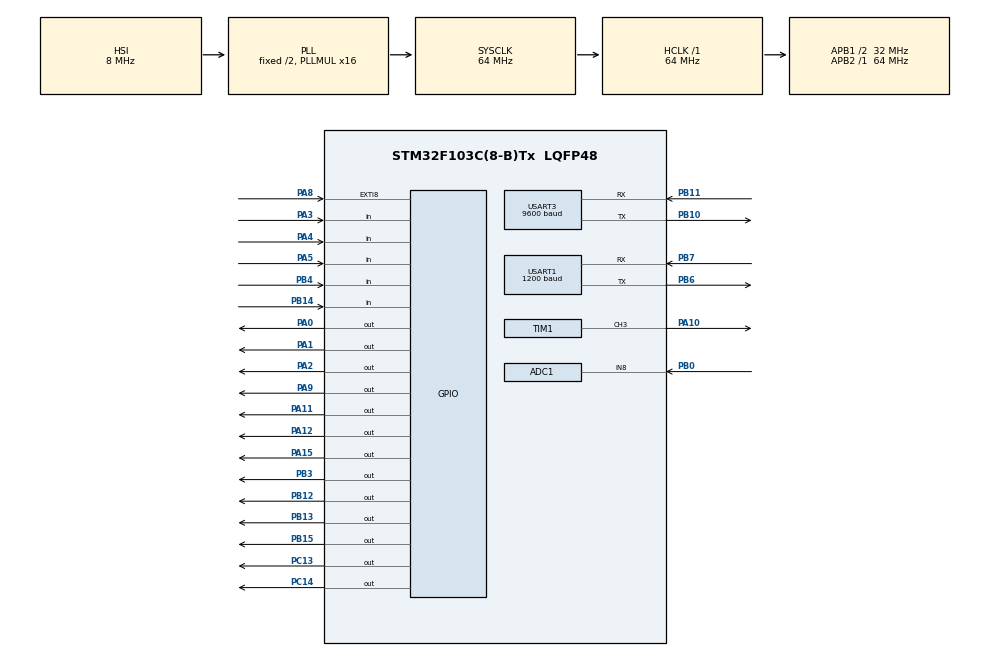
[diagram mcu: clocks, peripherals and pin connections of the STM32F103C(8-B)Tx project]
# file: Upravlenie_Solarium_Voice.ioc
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ADC1.Channel-0\#ChannelRegularConversion=ADC_CHANNEL_8
ADC1.ContinuousConvMode=DISABLE
ADC1.DataAlign=ADC_DATAALIGN_RIGHT
ADC1.DiscontinuousConvMode=DISABLE
ADC1.EnableAnalogWatchDog=false
ADC1.EnableRegularConversion=ENABLE
ADC1.ExternalTrigConv=ADC_SOFTWARE_START
ADC1.InjNumberOfConversion=0
ADC1.NbrOfConversion=1
ADC1.NbrOfConversionFlag=1
ADC1.Rank-0\#ChannelRegularConversion=1
ADC1.SamplingTime-0\#ChannelRegularConversion=ADC_SAMPLETIME_1CYCLE_5
ADC1.ScanConvMode=ADC_SCAN_DISABLE
ADC1.master=1
IWDG.Prescaler=IWDG_PRESCALER_256
Mcu.Family=STM32F1
Mcu.Name=STM32F103C(8-B)Tx
Mcu.Package=LQFP48
NVIC.ADC1_2_IRQn=true\:0\:0\:false\:true\:true\:1\:true\:true\:true
NVIC.EXTI9_5_IRQn=true\:0\:0\:false\:false\:true\:true\:true\:true
NVIC.PriorityGroup=NVIC_PRIORITYGROUP_4
NVIC.USART1_IRQn=true\:0\:0\:false\:false\:true\:true\:true\:true
NVIC.USART3_IRQn=true\:0\:0\:false\:false\:true\:true\:true\:true
PA0-WKUP.Signal=GPIO_Output
PA1.Signal=GPIO_Output
PA10.Signal=S_TIM1_CH3
PA11.Signal=GPIO_Output
PA12.Signal=GPIO_Output
PA13.Mode=Serial_Wire
PA13.Signal=SYS_JTMS-SWDIO
PA14.Mode=Serial_Wire
PA14.Signal=SYS_JTCK-SWCLK
PA15.Signal=GPIO_Output
PA2.Signal=GPIO_Output
PA3.GPIO_PuPd=GPIO_PULLUP
PA3.Signal=GPIO_Input
PA4.GPIO_PuPd=GPIO_PULLUP
PA4.Signal=GPIO_Input
PA5.GPIO_PuPd=GPIO_PULLUP
PA5.Signal=GPIO_Input
PA8.GPIO_PuPd=GPIO_PULLUP
PA8.Signal=GPXTI8
PA9.Signal=GPIO_Output
PB0.Signal=ADCx_IN8
PB10.Mode=Asynchronous
PB10.Signal=USART3_TX
PB11.GPIO_PuPd=GPIO_PULLUP
PB11.Mode=Asynchronous
PB11.Signal=USART3_RX
PB12.Signal=GPIO_Output
PB13.Signal=GPIO_Output
PB14.Signal=GPIO_Input
PB15.Signal=GPIO_Output
PB3.Signal=GPIO_Output
PB4.Signal=GPIO_Input
PB6.Mode=Asynchronous
PB6.Signal=USART1_TX
PB7.GPIO_PuPd=GPIO_PULLUP
PB7.Mode=Asynchronous
PB7.Signal=USART1_RX
PC13-TAMPER-RTC.Signal=GPIO_Output
PC14-OSC32_IN.Signal=GPIO_Output
PD0-OSC_IN.Mode=HSE-External-Oscillator
PD0-OSC_IN.Signal=RCC_OSC_IN
PD1-OSC_OUT.Mode=HSE-External-Oscillator
PD1-OSC_OUT.Signal=RCC_OSC_OUT
ProjectManager.HeapSize=0x200
ProjectManager.StackSize=0x400
ProjectManager.TargetToolchain=STM32CubeIDE
RCC.ADCPresc=RCC_ADCPCLK2_DIV6
RCC.AHBFreq_Value=64000000
RCC.APB1CLKDivider=RCC_HCLK_DIV2
RCC.APB1Freq_Value=32000000
RCC.APB1TimFreq_Value=64000000
RCC.APB2Freq_Value=64000000
RCC.APB2TimFreq_Value=64000000
RCC.HCLKFreq_Value=64000000
RCC.PLLMUL=RCC_PLL_MUL16
RCC.SYSCLKFreq_VALUE=64000000
RCC.SYSCLKSource=RCC_SYSCLKSOURCE_PLLCLK
RCC.USBFreq_Value=64000000
SH.ADCx_IN8.0=ADC1_IN8,IN8
SH.S_TIM1_CH3.0=TIM1_CH3,PWM Generation3 CH3
TIM1.AutoReloadPreload=TIM_AUTORELOAD_PRELOAD_ENABLE
TIM1.Channel-PWM\ Generation3\ CH3=TIM_CHANNEL_3
TIM1.ClockDivision=TIM_CLOCKDIVISION_DIV1
TIM1.CounterMode=TIM_COUNTERMODE_DOWN
TIM1.OCMode_PWM-PWM\ Generation3\ CH3=TIM_OCMODE_PWM2
TIM1.OCPolarity_3=TIM_OCPOLARITY_LOW
TIM1.Period=31000
TIM1.Prescaler=19
TIM1.Pulse-PWM\ Generation3\ CH3=8000
TIM2.AutoReloadPreload=TIM_AUTORELOAD_PRELOAD_ENABLE
TIM2.Period=5000
TIM2.Prescaler=16
USART1.BaudRate=1200
USART1.VirtualMode=VM_ASYNC
USART3.BaudRate=9600
USART3.VirtualMode=VM_ASYNC
VP_IWDG_VS_IWDG.Mode=IWDG_Activate
VP_TIM1_VS_ClockSourceINT.Mode=Internal
VP_TIM2_VS_ClockSourceINT.Mode=Internal
board=Upravlenie_Solarium_Voice

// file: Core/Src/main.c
/* USER CODE BEGIN Header */
/**
  ******************************************************************************
  * @file           : main.c
  * @brief          : Main program body
  ******************************************************************************
  * @attention
  *
  * Copyright (c) 2024 STMicroelectronics.
  * All rights reserved.
  *
  * This software is licensed under terms that can be found in the LICENSE file
  * in the root directory of this software component.
  * If no LICENSE file comes with this software, it is provided AS-IS.
  *
  ******************************************************************************
  */
/* USER CODE END Header */
#include "main.h"

/* USER CODE BEGIN Includes */
#include "string.h"
#include "max7219.h"
#include "LedControl.h"
#include "math.h"
#include "DFPlayer.h"
#include "eeprom.h"
#include "stdlib.h"

#define INPUT_INTERNAL 	(0)
#define INPUT_EXTERNAL 	(1)
#define STATUS_FREE    (0L)
#define STATUS_WAITING (3L)
#define STATUS_WORKING (1L)
#define STATUS_COOLING (2L)
#define MULTIPLIER     (1)
#define START_COUNTER_TIME  (1000L*MULTIPLIER)
#define ENTER_SERVICE_DELAY (2000L*MULTIPLIER)
#define SERVICE_NEXT_DELAY  (400*MULTIPLIER)
#define EXIT_SERVICE_TIME   (1200L*MULTIPLIER)
#define START_DELAY         (200L*MULTIPLIER)

// Virtual addreses
#define ADDRESS_HOURS_H		1
#define ADDRESS_HOURS_L		2
#define ADDRESS_MINUTES		3
#define ADDRESS_ADDRESSE	4
#define ADDRESS_PRE_TIME	5
#define ADDRESS_COOL_TIME	6
#define ADDRESS_EXT_MODE	7
#define ADDRESS_TEMP_MIN	8
#define ADDRESS_TEMP_MAX	9

// Buttons
#define BUTTON_PLUS      (1<<0x02)
#define BUTTON_MINUS     (1<<0x03)
#define BUTTON_START     (1<<0x00)
#define BUTTON_STOP      (1<<0x01)

#define BUTTON_AQUA      (1<<0x08)
#define BUTTON_FAN_PLUS  (1<<0x06)
#define BUTTON_FAN_MINUS (1<<0x07)
#define BUTTON_VOL_PLUS  (1<<0x04)
#define BUTTON_VOL_MINUS (1<<0x05)

#define ON 100
#define OFF 0
/* USER CODE END Includes */

ADC_HandleTypeDef hadc1;

IWDG_HandleTypeDef hiwdg;

TIM_HandleTypeDef htim1;
TIM_HandleTypeDef htim2;

UART_HandleTypeDef huart1;
UART_HandleTypeDef huart3;

/* USER CODE BEGIN PV */
/* Private variables ---------------------------------------------------------*/
int key_states;
LedControl led_control;
__IO uint32_t TimingDelay;
int tim_reload_value = 31000;
int Gv_SystickCounter;
volatile uint32_t g_ADCValue;
volatile uint32_t raw_temp;
volatile uint32_t g_ADCMeanValue;
uint32_t g_MeasurementNumber;
uint32_t g_Temperature;
unsigned char selected_unput;

unsigned char controller_address = 0x0e;
int curr_status;
int prev_status;
int curr_time;
int flash_mode = 0;
int dac_out_counter;
int dac_ping_pong_state;
int dac_prev_ping_pong_state;
int dac_current_block;
int dac_current_message;
int fade_out_counter;
int fade_in_counter;
int silence_counter;
int colaruim_lamps_state;
int lamps_state;

uint16_t data = 0;
unsigned char  time_to_set = 0;
unsigned int   work_hours[3] = {0,0,0}; //HH HL MM - Hours[2], Minutes[1]
unsigned char  preset_pre_time = 7;
unsigned char  preset_cool_time = 3;
unsigned char  temp_min_threshold;
unsigned char  temp_max_threshold;
unsigned char  ext_mode = 0;
unsigned char  lamps_mode = 0;
unsigned char  temperature_current;
unsigned char  last_rx_address;
unsigned int   error_code;
int start_counter = 0;
int last_button = 0;
int prev_button = 0;
int display_data;
int pre_time, main_time, cool_time;
unsigned int Gv_miliseconds = 0;
int Gv_UART_Timeout = 1000; // Timeout in mSec
int pre_time_sent = 0, main_time_sent = 0, cool_time_sent = 0;
int rx_state= 0;
int percent_aquafresh = 0, percent_licevi = 0, percent_fan1 = 0, percent_fan2 = 0;
int minute_counter =0;
int zero_crossed = 0;
int aqua_fresh_level = 0;
volatile int volume_level = 5;
volatile int fan_level = 7;
uint32_t tim_base=7; // Timer 2 time delay
unsigned int external_read = 0;
static int startup_delay = 0;
static int stop_delay = 0;
int current_folder_index, current_file_index;

char digits[3];
// for Display:
int refresh_counter = 0;
int flash_counter = 0;
// for Display:
int led_counter = 0;
int digit_num = 0;
__IO uint32_t LsiFreq = 40000;

/* Application general parameters */
#define VDD_APPLI                      ((uint32_t) 3300)    /* Value of analog voltage supply Vdda (unit: mV) */
#define RANGE_8BITS                    ((uint32_t)  255)    /* Max digital value for a full range of 8 bits */
#define RANGE_12BITS                   ((uint32_t) 4095)    /* Max digital value for a full range of 12 bits */

/* ADC parameters */
#define ADCCONVERTEDVALUES_BUFFER_SIZE ((uint32_t)  256)    /* Size of array containing ADC converted values */
#define ADC_36_6_DEGREE_VALUE (1024 - 0x617)
#define ADC_0_DEGREE_VALUE (1024 - 0xB70)

/* USER CODE END PV */

void SystemClock_Config(void);
static void MX_GPIO_Init(void);
static void MX_ADC1_Init(void);
static void MX_IWDG_Init(void);
static void MX_TIM1_Init(void);
static void MX_TIM2_Init(void);
static void MX_USART1_UART_Init(void);
static void MX_USART3_UART_Init(void);
static void MX_NVIC_Init(void);
/* USER CODE BEGIN PFP */
/* Private function prototypes -----------------------------------------------*/
void read_settings(void);
void write_settings(void);
void read_stored_time(void);
void write_stored_time(void);
float analog2tempBed(int raw);
/* USER CODE END PFP */

/* USER CODE BEGIN 0 */
int ToBCD(int value);
//void write_eeprom(void);
//void read_eeprom(void);
void ProcessButtons(void);
void update_status(void);
void set_start_out_signal(int value);
void set_lamps(int value);
void set_colarium_lamps(int value);
void set_fan1(int value);
void set_fan2(int value);
void set_aquafresh(int value);
void set_volume(int value);
void play_message(int folder_index, int file_index);
void new_read_eeprom(void);
void new_write_eeprom(void);
typedef struct time_str{
	 uint16_t hours_h;
	 uint16_t hours_l;
	 uint16_t minutes;
}time_str;
typedef struct settings_str{
	 uint16_t addresse;
	 uint16_t pre_time;
	 uint16_t cool_time;
	 uint16_t ext_mode;
	 uint16_t volume;
	 uint16_t temperatue_max;
}settings_str;
typedef struct flash_struct{
	 time_str time;
	 settings_str settings;
}flash_struct;
flash_struct flash_data;
uint16_t VirtAddVarTab[] = {1,2,3,4,5,6,7,8,9,10,11,12,13,14};//sizeof(flash_data)/2];

typedef enum ext_modes {ext_mode_none, ext_mode_colarium}ext_modes;
typedef enum lamps_modes {lamps_all, lamps_uv, lamps_colagen}lamps_modes;
typedef enum states {state_show_time,state_set_time,state_show_hours,state_enter_service,state_clear_hours,state_address,state_pre_time,state_cool_time,state_ext_mode, state_min_temp, state_max_temp}states;
states state;
typedef enum modes {mode_null,mode_clear_hours,mode_set_address,mode_set_pre_time,mode_set_cool_time, mode_set_ext_mode, mode_set_min_temp, mode_set_max_temp}modes;
modes service_mode;
typedef enum voice_messages { message_none, message_power_up, message_start_working, message_hurry_up, message_stop_working }voice_messages;
int useUart=0;

char key_readings[9];
char col_index;
char row_index;
void scan_keys()
{
	for(col_index = 0; col_index < 3; col_index++)
	{
		if(col_index == 0)
		{
			HAL_GPIO_WritePin(GPIOA, GPIO_PIN_1|GPIO_PIN_2, GPIO_PIN_SET);
			HAL_GPIO_WritePin(GPIOA, GPIO_PIN_0, GPIO_PIN_RESET);
		}
		if(col_index == 1)
		{
			HAL_GPIO_WritePin(GPIOA, GPIO_PIN_0|GPIO_PIN_2, GPIO_PIN_SET);
			HAL_GPIO_WritePin(GPIOA, GPIO_PIN_1, GPIO_PIN_RESET);
		}
		if(col_index == 2)
		{
			HAL_GPIO_WritePin(GPIOA, GPIO_PIN_0|GPIO_PIN_1, GPIO_PIN_SET);
			HAL_GPIO_WritePin(GPIOA, GPIO_PIN_2, GPIO_PIN_RESET);
		}
		for(row_index = 0; row_index < 3; row_index++)
		{
			if(row_index == 0)
			{
				key_readings[row_index + col_index*3] = (key_readings[row_index + col_index*3] << 1) | HAL_GPIO_ReadPin(GPIOA, GPIO_PIN_3);
			}
			if(row_index == 1)
			{
				key_readings[row_index + col_index*3] = (key_readings[row_index + col_index*3] << 1) | HAL_GPIO_ReadPin(GPIOA, GPIO_PIN_4);
			}
			if(row_index == 2)
			{
				key_readings[row_index + col_index*3] = (key_readings[row_index + col_index*3] << 1) | HAL_GPIO_ReadPin(GPIOA, GPIO_PIN_5);
			}

			if(key_readings[row_index + col_index*3] == 0x00)
			{
				key_states |= 1 << (row_index + col_index*3);
			}
			if(key_readings[row_index + col_index*3] == 0xFF)
			{
				key_states &= ~(1 << (row_index + col_index*3));
			}
		}
	}
	last_button = key_states;
}

char bar_conversion_table[] = {0x00, 0x00, 0x00, 0x80, 0x81, 0x83, 0x87, 0x8F, 0x9F, 0xBF, 0xFF};

void ShowBarIndicators(unsigned char bar1, unsigned char bar2)
{
	  unsigned char val = 0;
	  if(bar1 > 10) bar1 = 10;
	  if (bar2 > 10) bar2 = 10;
//	  LedControl_setRow(&led_control, 0, 3, (1<<(bar1-3)) - 1);
	  LedControl_setRow(&led_control, 0, 3, bar_conversion_table[bar1]);
	  LedControl_setRow(&led_control, 0, 5, bar_conversion_table[bar2]);
	  if(bar2 > 0) val |= 0x08;
	  if(bar2 > 1) val |= 0x10;
	  if(bar1 > 0) val |= 0x20;
	  if(bar1 > 1) val |= 0x40;

	  LedControl_setRow(&led_control, 0, 4, val);
}

char display_buffer[16];

void show_level(int level){
  unsigned char val = 0;
  if (level == 1)
  {
	  val = 0x0f;
  }
  else if (level >= 2)
  {
	  val = 0xff;
  }
  LedControl_setRow(&led_control, 0, 6, val);
}
void show_digit(int digit){
	digit = digit & 0x0F;
}

void SelectInput(unsigned char input)
{
	if(input == INPUT_INTERNAL)
	{
		selected_unput = INPUT_INTERNAL;
		HAL_GPIO_WritePin(GPIOB, GPIO_PIN_3, GPIO_PIN_RESET);
		HAL_GPIO_WritePin(GPIOC, GPIO_PIN_13, GPIO_PIN_RESET);
		HAL_GPIO_WritePin(GPIOC, GPIO_PIN_14, GPIO_PIN_RESET);

	}
	else
	{
		selected_unput = INPUT_EXTERNAL;

	}
}

/* USER CODE END 0 */

int main(void)
{

	__disable_irq();

  /* MCU Configuration--------------------------------------------------------*/

  /* Reset of all peripherals, Initializes the Flash interface and the Systick. */
  HAL_Init();

  /* USER CODE BEGIN Init */
	digits[0] = 0;
	digits[1] = 1;
	digits[2] = 2;
	prev_status = 0;
	state = state_show_time;
	pre_time = 0;
	main_time = 0;
	cool_time = 0;
	dac_current_message = -1;

	update_status();
	set_volume(0);

  /* USER CODE END Init */

  /* Configure the system clock */
  SystemClock_Config();

  /* Initialize all configured peripherals */
  MX_GPIO_Init();
  MX_ADC1_Init();
  MX_IWDG_Init();
  MX_TIM1_Init();
  MX_TIM2_Init();
  MX_USART1_UART_Init();
  MX_USART3_UART_Init();

  /* Initialize interrupts */
  MX_NVIC_Init();
  /* USER CODE BEGIN 2 */

  /* Unlock the Flash Program Erase controller */
  HAL_FLASH_Unlock();
  EE_Init();

  read_settings();
  read_stored_time();
  if (!preset_pre_time || !preset_cool_time) {
	  preset_pre_time = 7;
	  preset_cool_time = 3;
	  write_settings();// Paranoia check
  }

  __HAL_UART_ENABLE(&huart1);
  __HAL_UART_ENABLE(&huart3);
//  HAL_TIM_Base_Start(&htim1);
//  HAL_TIM_PWM_Start(&htim1,TIM_CHANNEL_3);
    set_fan1(0);
  /* Enable the UART Parity Error Interrupt */
    __HAL_UART_ENABLE_IT(&huart1, UART_IT_PE);

    /* Enable the UART Error Interrupt: (Frame error, noise error, overrun error) */
    __HAL_UART_ENABLE_IT(&huart1, UART_IT_ERR);

    /* Enable the UART Data Register not empty Interrupt */
    __HAL_UART_ENABLE_IT(&huart1, UART_IT_RXNE);
    HAL_NVIC_SetPriority(USART1_IRQn, 3, 0);
    __enable_irq();
	LedControl_init(&led_control, 15, GPIOB, 13, GPIOB, 12, GPIOB, 1);
	LedControl_shutdown(&led_control, 0, 0); //Turn ON
	LedControl_setIntensity(&led_control, 0, 8);
	LedControl_clearDisplay(&led_control, 0);
	LedControl_setDigit(&led_control, 0, 0, display_data & 0x0f, 0);
	LedControl_setDigit(&led_control, 0, 1, (display_data>>4) & 0x0f, 0);
	LedControl_setDigit(&led_control, 0, 2, (display_data>>8) & 0x0f, 0);
	HAL_Delay(1000);
	DFPlayerInit();
	SelectInput(INPUT_INTERNAL);
	HAL_GPIO_WritePin(GPIOC, GPIO_PIN_14, GPIO_PIN_SET); // MP3 Player select
//	DFPlayerEexecCMD(0x0D, 0, 0);
//	DFPlayerEexecCMD(0x0F, 01, 01);

	play_message(1, message_power_up);
  /* USER CODE END 2 */

  /* Infinite loop */
  /* USER CODE BEGIN WHILE */
//	HAL_Delay(1000);
//	SelectInput(INPUT_EXTERNAL);
	while (1)
	{
    /* USER CODE END WHILE */

    /* USER CODE BEGIN 3 */
		scan_keys();
		if ((state < state_enter_service) && ((flash_counter >> 4) & 1))
		{
			if (controller_address == 15) {
				external_read = (external_read << 1) | (!!(GPIOB->IDR & GPIO_IDR_IDR7));
				if (!main_time && (!external_read)) {
					if (curr_status != STATUS_COOLING) {
						main_time = -1;
						cool_time = preset_cool_time;
						Gv_miliseconds = 0;
						flash_mode = 0;
						state = state_set_time;
						update_status();
					}
				}
				if (main_time && !~external_read) {
					main_time = 0;
					Gv_miliseconds = 0;
					update_status();
				}
			}
		}
		HAL_GPIO_TogglePin(GPIOB, GPIO_PIN_9);
		ProcessButtons();
		switch (state) {
		case state_show_time:
		case state_set_time:
			if (!pre_time && !main_time && !cool_time) {
				flash_mode = 0;
				state = state_set_time;
				display_data = ToBCD(time_to_set);
				//				display_data = ToBCD(last_button); //Debug
			}
			else if (!pre_time && !main_time && cool_time)
			{
				if(flash_counter & 0x20)
				{
					display_data = 0xFFF;
				}
				else
				{
					display_data = ToBCD(abs(cool_time));
				}
			}
			else {
				state = state_show_time;
				//				  time_to_set = 0;
				display_data = ToBCD(abs(main_time));
				//				display_data = ToBCD(last_button); //Debug
			}
			break;
		case state_show_hours:

			if (flash_mode != 3) {
				flash_mode = 3; // All flashing
			}
			{
				int index = ((flash_counter / 0x30)) % 8;
				if ((index < 6) && (index & 1)) {
					display_data = ToBCD(work_hours[index/2]);
				}
				else {
					display_data = 0xFFF;
				}
			}
			break;
		case state_enter_service:
			display_data = service_mode | 0xF0;
			flash_mode = 0;
			break;

		case state_clear_hours:
			//			flash_mode = 3;
			if ((flash_counter / 0x30) & 1) {
				display_data = 0xFFC;
			}
			else {
				display_data = 0xFFF;
			}
			break;
		case state_address:
			flash_mode = 0;
			if ((flash_counter / 0x30) & 1) {
				if (controller_address != 15) { // Address 15 reserved for external control
					display_data = controller_address;
				}
				else {
					display_data = 0xEAF;
				}
			}
			else {
				display_data = 0xFFA;
			}
			break;
		case state_pre_time:
			//			flash_mode = 3;
			if ((flash_counter / 0x30) & 1) {
				display_data = preset_pre_time;
			}
			else {
				display_data = 0xFF3;
			}
			break;
		case state_cool_time:
			//			flash_mode = 3;
			if ((flash_counter / 0x30) & 1) {
				display_data = preset_cool_time;
			}
			else {
				display_data = 0xFF4;
			}
			break;
		case state_ext_mode:
			//			flash_mode = 0;
			if ((flash_counter / 0x30) & 1) {
				display_data = ext_mode;
			}
			else {
				display_data = 0xFF5;
			}
			break;

		case state_min_temp:
			//			flash_mode = 0;
			if ((flash_counter / 0x30) & 1) {
				display_data = ToBCD(temp_min_threshold);
			}
			else {
				display_data = 0xFF6;
			}
			break;

		case state_max_temp:
			//			flash_mode = 0;
			if ((flash_counter / 0x30) & 1) {
				display_data = ToBCD(temp_max_threshold);
			}
			else {
				display_data = 0xFF7;
			}
			break;
		}
		//		show_digit(display_data);
		if (state == state_show_time) {
			if (!(pre_time || main_time || cool_time)) {
				// Some Paranoia...
				// turn off all
				set_lamps(OFF);
				set_colarium_lamps(OFF);
				percent_fan1 = 0;
				set_fan1(0);
				set_fan2(0);
				set_aquafresh(0);
				lamps_mode = lamps_all;

				//				state = state_set_time;
			}
		}
		//
		//		while (USART_GetFlagStatus(USART1, USART_FLAG_RXNE) == RESET); // wAIT UNTIL RX BUFFER IS EMPTY
		//		int data =  USART_ReceiveData(USART1);
		//		USART_SendData(USART1,0x80);
		//				while (USART_GetFlagStatus(USART1, USART_FLAG_TXE) == RESET); // wAIT UNTIL TX BUFFER IS EMPTY
		if (pre_time) {
			// Indicate pre_time by moving bars
			ShowBarIndicators((flash_counter >> 4) %10, (flash_counter >> 4) % 10);
		}
		else {
			ShowBarIndicators(volume_level, fan_level);
		}
		show_level(aqua_fresh_level);
		HAL_ADC_Start_IT(&hadc1);
		HAL_Delay(10);

//		display_data = 0xFFF;
//		for(int i = 0; i < 9; i++)
//		{
//			if (!key_readings[i])
//			{
//				display_data = i;
//				break;
//			}
//
//		}

		//Uncomment to check temperature
		if ((last_button == BUTTON_STOP) && (curr_status == STATUS_FREE))
		{
			if(aqua_fresh_level == 0)
			{
				display_data = ToBCD(g_Temperature);
			}
			else
			{
				display_data = g_ADCMeanValue;
			}
		}
		if(error_code)
		{
			display_data = error_code;
		}
		LedControl_setDigit(&led_control, 0, 0, display_data & 0x0f, 0);
		LedControl_setDigit(&led_control, 0, 1, (display_data>>4) & 0x0f, 0);
		LedControl_setDigit(&led_control, 0, 2, (display_data>>8) & 0x0f, 0);
		flash_counter++;
		if(	(temp_max_threshold > 0) && (g_Temperature > 0))
		{
			if((g_Temperature > temp_max_threshold))
			{
				percent_fan1 = 10;
				set_fan1(percent_fan1);
				if(curr_status == STATUS_WORKING)
				{
					main_time = 0;
					pre_time = 0;
					update_status();
				}
				error_code = 0xFE1;
			}
			else
			{
				if((main_time == 0) && (cool_time == 0) && (percent_fan1 > 0))
				{
					percent_fan1 = 0;
					set_fan1(0);
				}
			}
		}
		if((curr_status == STATUS_WORKING) && (percent_fan1 == 0) && (temp_min_threshold > 0) && (g_Temperature > temp_min_threshold))
		{
			percent_fan1 = 3;
			set_fan1(percent_fan1);
		}
		/* Reload IWDG counter */
//		IWDG_ReloadCounter();
		HAL_IWDG_Refresh(&hiwdg);
		HAL_GPIO_WritePin(GPIOB, GPIO_PIN_9, GPIO_PIN_RESET); // Disable external reset connected to PB9

	}
  /* USER CODE END 3 */
}

void SystemClock_Config(void)
{
  RCC_OscInitTypeDef RCC_OscInitStruct = {0};
  RCC_ClkInitTypeDef RCC_ClkInitStruct = {0};
  RCC_PeriphCLKInitTypeDef PeriphClkInit = {0};

  /** Initializes the RCC Oscillators according to the specified parameters
  * in the RCC_OscInitTypeDef structure.
  */
  RCC_OscInitStruct.OscillatorType = RCC_OSCILLATORTYPE_HSI|RCC_OSCILLATORTYPE_LSI;
  RCC_OscInitStruct.HSIState = RCC_HSI_ON;
  RCC_OscInitStruct.HSICalibrationValue = RCC_HSICALIBRATION_DEFAULT;
  RCC_OscInitStruct.LSIState = RCC_LSI_ON;
  RCC_OscInitStruct.PLL.PLLState = RCC_PLL_ON;
  RCC_OscInitStruct.PLL.PLLSource = RCC_PLLSOURCE_HSI_DIV2;
  RCC_OscInitStruct.PLL.PLLMUL = RCC_PLL_MUL16;
  if (HAL_RCC_OscConfig(&RCC_OscInitStruct) != HAL_OK)
  {
    Error_Handler();
  }

  /** Initializes the CPU, AHB and APB buses clocks
  */
  RCC_ClkInitStruct.ClockType = RCC_CLOCKTYPE_HCLK|RCC_CLOCKTYPE_SYSCLK
                              |RCC_CLOCKTYPE_PCLK1|RCC_CLOCKTYPE_PCLK2;
  RCC_ClkInitStruct.SYSCLKSource = RCC_SYSCLKSOURCE_PLLCLK;
  RCC_ClkInitStruct.AHBCLKDivider = RCC_SYSCLK_DIV1;
  RCC_ClkInitStruct.APB1CLKDivider = RCC_HCLK_DIV2;
  RCC_ClkInitStruct.APB2CLKDivider = RCC_HCLK_DIV1;

  if (HAL_RCC_ClockConfig(&RCC_ClkInitStruct, FLASH_LATENCY_2) != HAL_OK)
  {
    Error_Handler();
  }
  PeriphClkInit.PeriphClockSelection = RCC_PERIPHCLK_ADC;
  PeriphClkInit.AdcClockSelection = RCC_ADCPCLK2_DIV6;
  if (HAL_RCCEx_PeriphCLKConfig(&PeriphClkInit) != HAL_OK)
  {
    Error_Handler();
  }
}

/**
  * @brief NVIC Configuration.
  * @retval None
  */
static void MX_NVIC_Init(void)
{
  /* ADC1_2_IRQn interrupt configuration */
  HAL_NVIC_SetPriority(ADC1_2_IRQn, 0, 0);
  HAL_NVIC_EnableIRQ(ADC1_2_IRQn);
}

static void MX_ADC1_Init(void)
{

  ADC_ChannelConfTypeDef sConfig = {0};

  /** Common config
  */
  hadc1.Instance = ADC1;
  hadc1.Init.ScanConvMode = ADC_SCAN_DISABLE;
  hadc1.Init.ContinuousConvMode = DISABLE;
  hadc1.Init.DiscontinuousConvMode = DISABLE;
  hadc1.Init.ExternalTrigConv = ADC_SOFTWARE_START;
  hadc1.Init.DataAlign = ADC_DATAALIGN_RIGHT;
  hadc1.Init.NbrOfConversion = 1;
  if (HAL_ADC_Init(&hadc1) != HAL_OK)
  {
    Error_Handler();
  }

  /** Configure Regular Channel
  */
  sConfig.Channel = ADC_CHANNEL_8;
  sConfig.Rank = ADC_REGULAR_RANK_1;
  sConfig.SamplingTime = ADC_SAMPLETIME_1CYCLE_5;
  if (HAL_ADC_ConfigChannel(&hadc1, &sConfig) != HAL_OK)
  {
    Error_Handler();
  }

}

static void MX_IWDG_Init(void)
{

  hiwdg.Instance = IWDG;
  hiwdg.Init.Prescaler = IWDG_PRESCALER_256;
  hiwdg.Init.Reload = 4095;
  if (HAL_IWDG_Init(&hiwdg) != HAL_OK)
  {
    Error_Handler();
  }

}

static void MX_TIM1_Init(void)
{

  TIM_ClockConfigTypeDef sClockSourceConfig = {0};
  TIM_MasterConfigTypeDef sMasterConfig = {0};
  TIM_OC_InitTypeDef sConfigOC = {0};
  TIM_BreakDeadTimeConfigTypeDef sBreakDeadTimeConfig = {0};

  htim1.Instance = TIM1;
  htim1.Init.Prescaler = 19;
  htim1.Init.CounterMode = TIM_COUNTERMODE_DOWN;
  htim1.Init.Period = 31000;
  htim1.Init.ClockDivision = TIM_CLOCKDIVISION_DIV1;
  htim1.Init.RepetitionCounter = 0;
  htim1.Init.AutoReloadPreload = TIM_AUTORELOAD_PRELOAD_ENABLE;
  if (HAL_TIM_Base_Init(&htim1) != HAL_OK)
  {
    Error_Handler();
  }
  sClockSourceConfig.ClockSource = TIM_CLOCKSOURCE_INTERNAL;
  if (HAL_TIM_ConfigClockSource(&htim1, &sClockSourceConfig) != HAL_OK)
  {
    Error_Handler();
  }
  if (HAL_TIM_PWM_Init(&htim1) != HAL_OK)
  {
    Error_Handler();
  }
  sMasterConfig.MasterOutputTrigger = TIM_TRGO_RESET;
  sMasterConfig.MasterSlaveMode = TIM_MASTERSLAVEMODE_DISABLE;
  if (HAL_TIMEx_MasterConfigSynchronization(&htim1, &sMasterConfig) != HAL_OK)
  {
    Error_Handler();
  }
  sConfigOC.OCMode = TIM_OCMODE_PWM2;
  sConfigOC.Pulse = 8000;
  sConfigOC.OCPolarity = TIM_OCPOLARITY_LOW;
  sConfigOC.OCNPolarity = TIM_OCNPOLARITY_HIGH;
  sConfigOC.OCFastMode = TIM_OCFAST_DISABLE;
  sConfigOC.OCIdleState = TIM_OCIDLESTATE_RESET;
  sConfigOC.OCNIdleState = TIM_OCNIDLESTATE_RESET;
  if (HAL_TIM_PWM_ConfigChannel(&htim1, &sConfigOC, TIM_CHANNEL_3) != HAL_OK)
  {
    Error_Handler();
  }
  sBreakDeadTimeConfig.OffStateRunMode = TIM_OSSR_DISABLE;
  sBreakDeadTimeConfig.OffStateIDLEMode = TIM_OSSI_DISABLE;
  sBreakDeadTimeConfig.LockLevel = TIM_LOCKLEVEL_OFF;
  sBreakDeadTimeConfig.DeadTime = 0;
  sBreakDeadTimeConfig.BreakState = TIM_BREAK_DISABLE;
  sBreakDeadTimeConfig.BreakPolarity = TIM_BREAKPOLARITY_HIGH;
  sBreakDeadTimeConfig.AutomaticOutput = TIM_AUTOMATICOUTPUT_DISABLE;
  if (HAL_TIMEx_ConfigBreakDeadTime(&htim1, &sBreakDeadTimeConfig) != HAL_OK)
  {
    Error_Handler();
  }
  HAL_TIM_MspPostInit(&htim1);

}

static void MX_TIM2_Init(void)
{

  TIM_ClockConfigTypeDef sClockSourceConfig = {0};
  TIM_MasterConfigTypeDef sMasterConfig = {0};

  htim2.Instance = TIM2;
  htim2.Init.Prescaler = 16;
  htim2.Init.CounterMode = TIM_COUNTERMODE_UP;
  htim2.Init.Period = 5000;
  htim2.Init.ClockDivision = TIM_CLOCKDIVISION_DIV1;
  htim2.Init.AutoReloadPreload = TIM_AUTORELOAD_PRELOAD_ENABLE;
  if (HAL_TIM_Base_Init(&htim2) != HAL_OK)
  {
    Error_Handler();
  }
  sClockSourceConfig.ClockSource = TIM_CLOCKSOURCE_INTERNAL;
  if (HAL_TIM_ConfigClockSource(&htim2, &sClockSourceConfig) != HAL_OK)
  {
    Error_Handler();
  }
  sMasterConfig.MasterOutputTrigger = TIM_TRGO_RESET;
  sMasterConfig.MasterSlaveMode = TIM_MASTERSLAVEMODE_DISABLE;
  if (HAL_TIMEx_MasterConfigSynchronization(&htim2, &sMasterConfig) != HAL_OK)
  {
    Error_Handler();
  }

}

static void MX_USART1_UART_Init(void)
{

  huart1.Instance = USART1;
  huart1.Init.BaudRate = 1200;
  huart1.Init.WordLength = UART_WORDLENGTH_8B;
  huart1.Init.StopBits = UART_STOPBITS_1;
  huart1.Init.Parity = UART_PARITY_NONE;
  huart1.Init.Mode = UART_MODE_TX_RX;
  huart1.Init.HwFlowCtl = UART_HWCONTROL_NONE;
  huart1.Init.OverSampling = UART_OVERSAMPLING_16;
  if (HAL_UART_Init(&huart1) != HAL_OK)
  {
    Error_Handler();
  }

}

static void MX_USART3_UART_Init(void)
{

  huart3.Instance = USART3;
  huart3.Init.BaudRate = 9600;
  huart3.Init.WordLength = UART_WORDLENGTH_8B;
  huart3.Init.StopBits = UART_STOPBITS_1;
  huart3.Init.Parity = UART_PARITY_NONE;
  huart3.Init.Mode = UART_MODE_TX_RX;
  huart3.Init.HwFlowCtl = UART_HWCONTROL_NONE;
  huart3.Init.OverSampling = UART_OVERSAMPLING_16;
  if (HAL_UART_Init(&huart3) != HAL_OK)
  {
    Error_Handler();
  }

}

static void MX_GPIO_Init(void)
{
  GPIO_InitTypeDef GPIO_InitStruct = {0};

  /* GPIO Ports Clock Enable */
  __HAL_RCC_GPIOC_CLK_ENABLE();
  __HAL_RCC_GPIOD_CLK_ENABLE();
  __HAL_RCC_GPIOA_CLK_ENABLE();
  __HAL_RCC_GPIOB_CLK_ENABLE();

  /*Configure GPIO pin Output Level */
  HAL_GPIO_WritePin(GPIOC, GPIO_PIN_13|GPIO_PIN_14, GPIO_PIN_RESET);

  /*Configure GPIO pin Output Level */
  HAL_GPIO_WritePin(GPIOA, GPIO_PIN_0|GPIO_PIN_1|GPIO_PIN_2|GPIO_PIN_9
                          |GPIO_PIN_11|GPIO_PIN_12|GPIO_PIN_15, GPIO_PIN_RESET);

  /*Configure GPIO pin Output Level */
  HAL_GPIO_WritePin(GPIOB, GPIO_PIN_12|GPIO_PIN_13|GPIO_PIN_15|GPIO_PIN_3, GPIO_PIN_RESET);

  /*Configure GPIO pins : PC13 PC14 */
  GPIO_InitStruct.Pin = GPIO_PIN_13|GPIO_PIN_14;
  GPIO_InitStruct.Mode = GPIO_MODE_OUTPUT_PP;
  GPIO_InitStruct.Pull = GPIO_NOPULL;
  GPIO_InitStruct.Speed = GPIO_SPEED_FREQ_LOW;
  HAL_GPIO_Init(GPIOC, &GPIO_InitStruct);

  /*Configure GPIO pins : PA0 PA1 PA2 PA9
                           PA11 PA12 PA15 */
  GPIO_InitStruct.Pin = GPIO_PIN_0|GPIO_PIN_1|GPIO_PIN_2|GPIO_PIN_9
                          |GPIO_PIN_11|GPIO_PIN_12|GPIO_PIN_15;
  GPIO_InitStruct.Mode = GPIO_MODE_OUTPUT_PP;
  GPIO_InitStruct.Pull = GPIO_NOPULL;
  GPIO_InitStruct.Speed = GPIO_SPEED_FREQ_LOW;
  HAL_GPIO_Init(GPIOA, &GPIO_InitStruct);

  /*Configure GPIO pins : PA3 PA4 PA5 */
  GPIO_InitStruct.Pin = GPIO_PIN_3|GPIO_PIN_4|GPIO_PIN_5;
  GPIO_InitStruct.Mode = GPIO_MODE_INPUT;
  GPIO_InitStruct.Pull = GPIO_PULLUP;
  HAL_GPIO_Init(GPIOA, &GPIO_InitStruct);

  /*Configure GPIO pins : PB12 PB13 PB15 PB3 */
  GPIO_InitStruct.Pin = GPIO_PIN_12|GPIO_PIN_13|GPIO_PIN_15|GPIO_PIN_3;
  GPIO_InitStruct.Mode = GPIO_MODE_OUTPUT_PP;
  GPIO_InitStruct.Pull = GPIO_NOPULL;
  GPIO_InitStruct.Speed = GPIO_SPEED_FREQ_LOW;
  HAL_GPIO_Init(GPIOB, &GPIO_InitStruct);

  /*Configure GPIO pins : PB14 PB4 */
  GPIO_InitStruct.Pin = GPIO_PIN_14|GPIO_PIN_4;
  GPIO_InitStruct.Mode = GPIO_MODE_INPUT;
  GPIO_InitStruct.Pull = GPIO_NOPULL;
  HAL_GPIO_Init(GPIOB, &GPIO_InitStruct);

  /*Configure GPIO pin : PA8 */
  GPIO_InitStruct.Pin = GPIO_PIN_8;
  GPIO_InitStruct.Mode = GPIO_MODE_IT_RISING;
  GPIO_InitStruct.Pull = GPIO_PULLUP;
  HAL_GPIO_Init(GPIOA, &GPIO_InitStruct);

  /* EXTI interrupt init*/
  HAL_NVIC_SetPriority(EXTI9_5_IRQn, 0, 0);
  HAL_NVIC_EnableIRQ(EXTI9_5_IRQn);

}

/* USER CODE BEGIN 4 */

int ToBCD(int value){
	int digits[3];
	int result;
	digits[0] = value %10;
	digits[1] = (value/10) % 10;
	digits[2] = (value/100) % 10;
	result = digits[0] | (digits[1]<<4) | (digits[2]<<8);
	return result;
}

int FromBCD(int value){
	int digits[3];
	int result;
	digits[0] = value & 0x0F;
	digits[1] = (value>>4) & 0x0F;
	digits[2] = (value>>8) & 0x0F;
	result = digits[0] + digits[1]*10 + digits[2]*100;
	return result;
}

void set_colarium_lamps(int value){
	lamps_state = value;
	if (value)	GPIOA->BSRR = GPIO_BSRR_BS11;
	else GPIOA->BSRR = GPIO_BSRR_BR11;
}
void set_lamps(int value){
	colaruim_lamps_state = value;
	if (value)	GPIOA->BSRR = GPIO_BSRR_BS12;
	else GPIOA->BSRR = GPIO_BSRR_BR12;
}
void set_fan2(int value){
	if (value)	GPIOA->BSRR = GPIO_BSRR_BS9;
	else GPIOA->BSRR = GPIO_BSRR_BR9;
}

void set_fan1(int value){
	//
	GPIO_InitTypeDef GPIO_InitStruct;
//	uint32 counter = 0xFFFFFFF;
//	TIM_Cmd(TIM2, DISABLE);
	int multiplier = 285;
	zero_crossed = 0;

//	while (!zero_crossed && (counter--));
	switch(value){
	case 10:
		tim_base = 60; //Reverse polarity
		break;
	case 9:
		tim_base = 37;
		break;
	case 8:
		tim_base = 43;
		break;
	case 7:
		tim_base = 48;
		break;
	case 6:
		tim_base = 52;
		break;
	case 5:
		tim_base = 56;
		break;
	case 4:
		tim_base = 59;
		break;
	case 3:
		tim_base = 62;
		break;
	case 2:
		tim_base = 63;
		break;
	case 1:
	default:
		tim_base = 65;
		break;
	case 0:
		tim_base = 0;
		break;
	}
//	if(value == 10) TIM_OCInitStructure.TIM_OCPolarity = TIM_OCPolarity_Low;
//	else  TIM_OCInitStructure.TIM_OCPolarity = TIM_OCPolarity_High;
//	TIM_TimeBaseStructure.TIM_Period = tim_base;
//	TIM_TimeBaseInit(TIM2, &TIM_TimeBaseStructure);
	/* TIM2 PWM2 Mode configuration: Channel4 */
	//for one pulse mode set PWM2, output enable, pulse (1/(t_wanted=TIM_period-TIM_Pulse)), set polarity high
//	if (value)	TIM_OCInitStructure.TIM_OutputState = TIM_OutputState_Enable;
//	else 	TIM_OCInitStructure.TIM_OutputState = TIM_OutputState_Disable;
//	if (TIM_TimeBaseStructure.TIM_Period) TIM_OCInitStructure.TIM_Pulse = TIM_TimeBaseStructure.TIM_Period-5;
//	else  TIM_OCInitStructure.TIM_Pulse = 9;

//	TIM_OC4Init(TIM2, &TIM_OCInitStructure);
//	if (value) TIM_Cmd(TIM2, ENABLE);
//	else TIM_Cmd(TIM2, DISABLE);
//	TIM_Cmd(TIM2, ENABLE);
	if(value == 0)
	{
		GPIO_InitStruct.Pin = GPIO_PIN_10;
		GPIO_InitStruct.Mode = GPIO_MODE_OUTPUT_PP;
		GPIO_InitStruct.Speed = GPIO_SPEED_FREQ_LOW;
		HAL_GPIO_Init(GPIOA, &GPIO_InitStruct);
		HAL_GPIO_WritePin(GPIOA, GPIO_PIN_10, GPIO_PIN_RESET);
	}
	else
	{
		MX_TIM1_Init();
		HAL_TIM_Base_Start(&htim1);
		HAL_TIM_PWM_Start(&htim1,TIM_CHANNEL_3);
		if(value == 10)
		{
			TIM1->CCR3 = TIM1->ARR -1;
		}
		else
		{
			TIM1->CCR3 = TIM1->ARR -(multiplier*tim_base);
		}
	}

}

void set_aquafresh(int value){

	if (value)	GPIOA->BSRR = GPIO_BSRR_BS15;
	else GPIOA->BSRR = GPIO_BSRR_BR15;
}

void set_volume(int value){

	volume_level = value;

	if(selected_unput == INPUT_INTERNAL)
	{
	//	DFPlayerEexecCMD(0x0F, 00, value*3);
	}
	else
	{
		switch(volume_level){
		case 10:
			HAL_GPIO_WritePin(GPIOC, GPIO_PIN_13, GPIO_PIN_SET);
			HAL_GPIO_WritePin(GPIOC, GPIO_PIN_14, GPIO_PIN_RESET);
			HAL_GPIO_WritePin(GPIOB, GPIO_PIN_3, GPIO_PIN_RESET);
			break;
		case 9:
			HAL_GPIO_WritePin(GPIOC, GPIO_PIN_13, GPIO_PIN_RESET);
			HAL_GPIO_WritePin(GPIOC, GPIO_PIN_14, GPIO_PIN_SET);
			HAL_GPIO_WritePin(GPIOB, GPIO_PIN_3, GPIO_PIN_RESET);
			break;
		case 8:
		case 7:
			HAL_GPIO_WritePin(GPIOC, GPIO_PIN_13, GPIO_PIN_SET);
			HAL_GPIO_WritePin(GPIOC, GPIO_PIN_14, GPIO_PIN_SET);
			HAL_GPIO_WritePin(GPIOB, GPIO_PIN_3, GPIO_PIN_RESET);
			break;
		case 6:
		case 5:
			HAL_GPIO_WritePin(GPIOC, GPIO_PIN_13, GPIO_PIN_RESET);
			HAL_GPIO_WritePin(GPIOC, GPIO_PIN_14, GPIO_PIN_RESET);
			HAL_GPIO_WritePin(GPIOB, GPIO_PIN_3, GPIO_PIN_SET);
			break;
		case 4:
		case 3:
			HAL_GPIO_WritePin(GPIOC, GPIO_PIN_13, GPIO_PIN_SET);
			HAL_GPIO_WritePin(GPIOC, GPIO_PIN_14, GPIO_PIN_RESET);
			HAL_GPIO_WritePin(GPIOB, GPIO_PIN_3, GPIO_PIN_SET);
			break;
		case 2:
			HAL_GPIO_WritePin(GPIOC, GPIO_PIN_13, GPIO_PIN_RESET);
			HAL_GPIO_WritePin(GPIOC, GPIO_PIN_14, GPIO_PIN_SET);
			HAL_GPIO_WritePin(GPIOB, GPIO_PIN_3, GPIO_PIN_SET);
			break;
		case 1:
		case 0:
		default:
			HAL_GPIO_WritePin(GPIOC, GPIO_PIN_13, GPIO_PIN_SET);
			HAL_GPIO_WritePin(GPIOC, GPIO_PIN_14, GPIO_PIN_SET);
			HAL_GPIO_WritePin(GPIOB, GPIO_PIN_3, GPIO_PIN_SET);
			break;
			break;

		}
	}
}

void usart1_IT_handler()
{
	 uint32_t isrflags   = READ_REG(USART1->SR);
	 uint32_t cr1its     = READ_REG(USART1->CR1);
	 uint32_t errorflags = 0x00U;
	 useUart = 1;
	 enum rxstates {rx_state_none, rx_state_pre_time, rx_state_main_time, rx_state_cool_time, rx_state_get_checksum};

	 /* If no error occurs */
	 errorflags = (isrflags & (uint32_t)(USART_SR_PE | USART_SR_FE | USART_SR_ORE | USART_SR_NE));
	 if(errorflags == RESET)
	 {
		 /* UART in mode Receiver -------------------------------------------------*/
		 if(((isrflags & USART_SR_RXNE) != RESET) && ((cr1its & USART_CR1_RXNEIE) != RESET))
		 {
			 data = USART1->DR & (uint16_t)0x00FF;
			 if ((data & 0x80)){
			 		last_rx_address = (data >> 3U)&0x0f;
			 		unsigned char addr_is_ok = 0;

			 		if(ext_mode == ext_mode_colarium){
			 			if(last_rx_address  == controller_address ){
			 				if (curr_status != STATUS_FREE ){
			 					if( lamps_mode == lamps_all) addr_is_ok = 1;
			 				}
			 				else {
			 					addr_is_ok = 1;
			 				}
			 			}
			 			if(last_rx_address  == controller_address + 1){
			 				if (curr_status != STATUS_FREE ){
			 					if( lamps_mode == lamps_uv) addr_is_ok = 1;
			 				}
			 				else {
			 					addr_is_ok = 1;
			 				}
			 			}
			 			if(last_rx_address  == controller_address + 2){
			 				if (curr_status != STATUS_FREE ){
			 					if( lamps_mode == lamps_colagen) addr_is_ok = 1;
			 				}
			 				else {
			 					addr_is_ok = 1;
			 				}
			 			}
			 		}
			 		else {
			 			addr_is_ok = (last_rx_address == controller_address);
			 		}
			 		if (!addr_is_ok) return;
			 		// Command
			 		if(addr_is_ok){
			 			Gv_UART_Timeout = 1500;
			 		}
			 		if((data & 0x07) == 0x00 ){ // Status
			 			data = (curr_status<<6)| ToBCD(curr_time);
			 //			data = (STATUS_WORKING<<6)|4;
			 			USART1->DR = data;
			 		}
			 		else if ((data & 0x07) == 1) //Command 1 - Start
			 		{
			 			pre_time = 0;
			 			update_status();
			 		}
			 		else if ((data & 0x07) == 2)  //Command 2 == Pre_time_set
			 		{
			 			rx_state = rx_state_pre_time;
			 		}
			 		else if ((data & 0x07) == 5) //Command 5 == Main_time_set
			 		{
			 			rx_state = rx_state_main_time;
			 		}
			 		else if ((data & 0x07) == 3) //Command 3 == Cool_time_set
			 		{
			 			rx_state = rx_state_cool_time;
			 		}

			 	} else if (rx_state){
			 		// payload
			 		int time_in_hex = ToBCD(main_time_sent);
			 		if(rx_state == rx_state_get_checksum){
			 			int checksum = (pre_time_sent + cool_time_sent  - time_in_hex - 5) & 0x7F;
			 			if(	data == checksum){
			 				pre_time = pre_time_sent;
			 				main_time = main_time_sent;
			 				cool_time = cool_time_sent;
			 				update_status();
			 				Gv_miliseconds = 0;
			 			}
			 			rx_state = 0;
			 		}
			 		if(rx_state == rx_state_pre_time){
			 			pre_time_sent = data;
			 			rx_state = 0;
			 		}
			 		if(rx_state == rx_state_main_time){
			 			main_time_sent = FromBCD(data);
			 			rx_state = 0;
			 			if (last_rx_address == controller_address)	lamps_mode = lamps_all;
			 			if (last_rx_address == controller_address+1)lamps_mode = lamps_uv;
			 			if (last_rx_address == controller_address+2)lamps_mode = lamps_colagen;

			 		}
			 		if(rx_state == rx_state_cool_time){
			 			cool_time_sent = data;
			 			rx_state = rx_state_get_checksum;
			 			int checksum = (pre_time_sent + cool_time_sent  - time_in_hex - 5) & 0x7F;
			 			data = checksum;
			 			USART1->DR = data;
			 		}

			 	}
		 }
	 }
	 else
	 {
		 rx_state= 0;
		 USART1->SR = 0; // Clear Errors
	 }
}

void play_message(int folder_index, int file_index){

	HAL_IWDG_Refresh(&hiwdg);
	HAL_GPIO_WritePin(GPIOB, GPIO_PIN_9, GPIO_PIN_RESET); // Disable external reset connected to PB9

	SelectInput(INPUT_INTERNAL);
	set_volume(7);
	DFPlayerEexecCMD(0x0F, folder_index, file_index);
	fade_in_counter =  1000;
	HAL_Delay(6000);
	SelectInput(INPUT_EXTERNAL);
	set_volume(volume_level);
}

/**
 * @brief  Manage the activity on buttons
 * @param  None
 * @retval None
 */
void ProcessButtons(void)
{

	if (last_button) {
		if (last_button != prev_button) {
			switch (last_button) {
			case BUTTON_START:
				if(error_code)
				{
					error_code = 0;
				}
				if (pre_time) {
					//send_start();
					Gv_miliseconds = 0;
					pre_time = 0;
					state = state_show_time;
					update_status();
					fan_level = 7;
					if((temp_min_threshold > 0) && (g_Temperature > 0) && (g_Temperature < temp_min_threshold))
					{
						percent_fan1 = 0;
					}
					else
					{
						percent_fan1 = fan_level;
					}
					set_fan1(percent_fan1);
				}
				if (!pre_time && !main_time && !cool_time) {
					if (controller_address == 15)
					{
						volatile static int counter;
						counter = 0x100000;

						while (counter)
						{
							counter--;
							USART1->DR = 0x00; // Send Start signal to Remote Control
						}
					}
					if (time_to_set) {
						// Send of time moved elsewhere
						pre_time = preset_pre_time;
						main_time = time_to_set;
						cool_time = preset_cool_time;
						state = state_show_time;
						time_to_set = 0;
						Gv_miliseconds = 0;
						update_status();
						//						play_message(0);
					}
					else {

							// Write EEPROM
						if (state == state_clear_hours)
						{
							work_hours[0] = 0;
							work_hours[1] = 0;
							work_hours[2] = 0;

							write_stored_time();
							start_counter = 0;
							service_mode = mode_null;
						}
						else if (state > state_enter_service)
						{
							write_settings();
							service_mode = mode_null;
							if (state == state_address) {
//								init_periph();
							}
							start_counter = 0;
						}
						else {
							start_counter = START_COUNTER_TIME;
						}
						state = state_show_hours;
						flash_counter = 0;
					}
				}
				break;
			case BUTTON_STOP:
				if (curr_status == STATUS_WORKING) {
					main_time = 0;
					pre_time = 0;
					update_status();
					percent_fan1 = 10;
					set_fan1(percent_fan1);
					aqua_fresh_level = 0;
					percent_aquafresh = 0;
				}
				if (state >= state_enter_service) {
					start_counter = 0;
					state = state_show_time;
					service_mode = mode_null;
				}
				break;
			case BUTTON_FAN_PLUS:
				if (curr_status == STATUS_WORKING) {
					if (fan_level < 10L) {
						fan_level++;
						percent_fan1 = fan_level;
						set_fan1(percent_fan1);
					}
				}
				break;
			case BUTTON_FAN_MINUS:
				if (curr_status == STATUS_WORKING) {
					if (fan_level > 1) {
						fan_level--;
						percent_fan1 = fan_level;
						set_fan1(percent_fan1);
					}
				}
				break;
			case BUTTON_AQUA:
#ifdef LICEVI_LAMPI_VMESTO_AQAFRESH
				if (minute_counter)
				{
					aqua_fresh_level = 0;
				}
#else
				aqua_fresh_level++;
				if (aqua_fresh_level > 2)aqua_fresh_level = 0;
#endif
				if (minute_counter) {
				}
				break;
			case BUTTON_VOL_PLUS:
				if (curr_status != STATUS_WAITING) {
					if (volume_level < 10L) {
						volume_level++;
						set_volume(volume_level);
					}
				}
				break;
			case BUTTON_VOL_MINUS:
				if (curr_status != STATUS_WAITING) {
					if (volume_level > 0) {
						volume_level--;
						set_volume(volume_level);
					}
				}
				break;
			case BUTTON_PLUS:
			{
				if (curr_status == STATUS_WORKING) {
					if (lamps_mode == lamps_all) {
						set_colarium_lamps(1);
					}
				}
				if (state == state_show_hours) {
					state = state_set_time;
					start_counter = 0;
				}
				if (state == state_set_time) {
					if (time_to_set < 25L) {
						if ((!useUart && (volume_level == 1)) && (controller_address != 15)) time_to_set++;
					}
					else
					{
						while (1);
					}
				}
				else if (state > state_enter_service) {
					start_counter = EXIT_SERVICE_TIME;
					switch (service_mode) {
					case mode_set_address:
						if (controller_address < 15) controller_address++;
						break;
					case mode_set_pre_time:
						if (preset_pre_time < 9) preset_pre_time++;
						break;
					case mode_set_cool_time:
						if (preset_cool_time < 9) preset_cool_time++;
						break;
					case mode_set_ext_mode:
						if (ext_mode < ext_mode_colarium) ext_mode++;
						break;
					case mode_set_min_temp:
						if (temp_min_threshold < 30) temp_min_threshold++;
						break;
					case mode_set_max_temp:
						if (temp_max_threshold < 99) temp_max_threshold++;
						break;
					default:
						break;
					}
				}

			}
			break;
			case BUTTON_MINUS:
				if (curr_status == STATUS_WORKING) {
					if (lamps_mode == lamps_all) {
						set_colarium_lamps(0);
					}
				}
				if (state == state_show_hours) {
					state = state_set_time;
					start_counter = 0;
				}
				if (state == state_set_time) {
					if (time_to_set) {
						if ((!useUart) && (controller_address != 15))  time_to_set--;
					}
				}
				else if (state > state_enter_service) {
					start_counter = EXIT_SERVICE_TIME;
					switch (service_mode) {
					case mode_set_address:
						if (controller_address) controller_address--;
						break;
					case mode_set_pre_time:
						if (preset_pre_time) preset_pre_time--;
						break;
					case mode_set_cool_time:
						if (preset_cool_time) preset_cool_time--;
						break;
					case mode_set_ext_mode:
						if (ext_mode > 0) ext_mode--;
						break;
					case mode_set_min_temp:
						if (temp_min_threshold > 0) temp_min_threshold--;
						break;
					case mode_set_max_temp:
						if (temp_max_threshold > 0) temp_max_threshold--;
						break;
					default:
						break;
					}
				}
				//				if(selected_led_bits & LED_FAN2_L){
				//					if(percent_fan2) percent_fan2 = 0;
				//					set_fan2(percent_fan2);
				//				} else if(selected_led_bits & LED_FAN1_L){
				//					if(percent_fan1) percent_fan1-=25;
				//					set_fan1(percent_fan1);
				//				}
				//				else if(selected_led_bits & LED_LICEVI_L){
				//					if(percent_licevi) percent_licevi=0;
				//					set_licevi_lamps(percent_licevi);
				//					update_status();
				//				}

				break;
			default:
				while (0);
			}
		}
	}
	prev_button = last_button;

	if (last_button == BUTTON_START)
	{
		// LED1_ON;
		if (start_counter < (START_COUNTER_TIME + ENTER_SERVICE_DELAY + 6 * SERVICE_NEXT_DELAY)) start_counter++;
		if (start_counter == START_COUNTER_TIME + ENTER_SERVICE_DELAY) {
			if (curr_status == STATUS_FREE && (state < state_enter_service))
			{
				state = state_enter_service;
				service_mode = mode_clear_hours; // Clear Hours
			}
		}
		if (state == state_enter_service) {
			if (start_counter == START_COUNTER_TIME + ENTER_SERVICE_DELAY + 1 * SERVICE_NEXT_DELAY) {
				service_mode = mode_set_address; //
			}
			else if (start_counter == START_COUNTER_TIME + ENTER_SERVICE_DELAY + 2 * SERVICE_NEXT_DELAY) {
				service_mode = mode_set_pre_time; //
			}
			else if (start_counter == START_COUNTER_TIME + ENTER_SERVICE_DELAY + 3 * SERVICE_NEXT_DELAY) {
				service_mode = mode_set_cool_time; //
			}
			else if (start_counter == START_COUNTER_TIME + ENTER_SERVICE_DELAY + 4 * SERVICE_NEXT_DELAY) {
				service_mode = mode_set_ext_mode; //
			}
			else if (start_counter == START_COUNTER_TIME + ENTER_SERVICE_DELAY + 5 * SERVICE_NEXT_DELAY) {
				service_mode = mode_set_min_temp; //
			}
			else if (start_counter == START_COUNTER_TIME + ENTER_SERVICE_DELAY + 6 * SERVICE_NEXT_DELAY) {
				service_mode = mode_set_max_temp; //
			}
		}
//		set_start_out_signal(1);
	}
	else
	{
//		set_start_out_signal(0);
		if (start_counter) {
			if (state == state_show_hours) {
				start_counter--;
				if (!start_counter) {
					state = state_show_time;
				}
			}
			else if (state >= state_enter_service) {
				if (state == state_enter_service) {
					state = service_mode + state_enter_service;
				}
				start_counter--;
				if (!start_counter) {
					state = state_show_time;
//					new_write_eeprom();
//					new_read_eeprom();
				}
			}
			else {
				start_counter = 0;

			}
		}
	}

	if (prev_status != curr_status) {
		if (curr_status == STATUS_WORKING) {
			if (controller_address != 15) {
				work_hours[2] += main_time;
				if (work_hours[2] > 59L) {
					work_hours[2] = work_hours[2] - 60;
					work_hours[1]++;
					if (work_hours[1] > 99L) {
						work_hours[1] = 0;
						work_hours[0]++;
					}
				}
				write_stored_time();
			}
			flash_mode = 0;
			percent_aquafresh = 0, percent_licevi = 100L, percent_fan2 = 100L;
			zero_crossed = 0;
			//			volume_level = 6;
			fan_level = 7;
			percent_fan1 = fan_level;
			if (lamps_mode == lamps_all) {
				set_lamps(100);
				set_colarium_lamps(100);
			}
			if (lamps_mode == lamps_uv) {
				set_lamps(100);
			}
			if (lamps_mode == lamps_colagen) {
				set_colarium_lamps(100);
			}
			zero_crossed = 0;
			if((temp_min_threshold > 0) && (g_Temperature > 0) && (g_Temperature < temp_min_threshold))
			{
				percent_fan1 = 0;
			}
			set_fan1(percent_fan1);
			set_fan2(percent_fan2);
			//			set_aquafresh(percent_aquafresh);
			play_message(1,message_start_working);
			set_volume(volume_level);
		}
		if (curr_status == STATUS_COOLING) {
			if (controller_address == 15) {
				work_hours[2] += abs(main_time);
				if (work_hours[2] > 59L) {
					work_hours[2] = work_hours[2] - 60;
					work_hours[1]++;
					if (work_hours[1] > 99L) {
						work_hours[1] = 0;
						work_hours[0]++;
					}
				}
				write_stored_time();

			}
			percent_licevi = 0, percent_fan1 = 10L, percent_fan2 = 100L;
			percent_aquafresh = 0;
			aqua_fresh_level = 0;
			zero_crossed = 0;
			set_lamps(OFF);
			//			zero_crossed = 0;
			stop_delay = 1000;
			//			set_colarium_lamps(0);
			fan_level = 10;
			set_fan1(percent_fan1);
			set_fan2(percent_fan2);
			set_aquafresh(0);
			flash_mode = 3;
			play_message(1,message_stop_working);

		}
		if (curr_status == STATUS_FREE) {
			percent_aquafresh = 0, percent_licevi = 0, percent_fan1 = 0, percent_fan2 = 0;
			aqua_fresh_level = 0;
			set_lamps(OFF);
			set_colarium_lamps(OFF);
			set_fan1(0);
			set_fan2(OFF);
			//			set_aquafresh(percent_aquafresh);
			minute_counter = 0;
			flash_mode = 0;
			lamps_mode = lamps_all;
		}
		prev_status = curr_status;

	}
	//    LED1_OFF;

}

void update_status(void) {
	if (pre_time) {
		curr_time = pre_time;
		curr_status = STATUS_WAITING;
#ifdef LICEVI_LAMPI_VMESTO_AQAFRESH
		aqua_fresh_level = 0;
#endif
	}
	else if (main_time) {
		curr_time = main_time;
		curr_status = STATUS_WORKING;
#ifdef LICEVI_LAMPI_VMESTO_AQAFRESH
		if (!minute_counter)aqua_fresh_level = 2;
#endif
	}
	else if (cool_time) {
		curr_time = cool_time;
		curr_status = STATUS_COOLING;
#ifdef LICEVI_LAMPI_VMESTO_AQAFRESH
		aqua_fresh_level = 0;
#endif
	}
	else {
		curr_time = 0;
		curr_status = STATUS_FREE;
#ifdef LICEVI_LAMPI_VMESTO_AQAFRESH
		aqua_fresh_level = 0;
#endif
	}
}

void HAL_GPIO_EXTI_Callback(uint16_t GPIO_Pin)
{
	if(tim_base == 0)
	{
		htim1.Instance->ARR = 0;
	}
	else
	{
		if(htim1.Instance->CNT > 10 )
		{
			//tim_reload_value++;
		}
		if(htim1.Instance->CNT < 5 )
		{
			//tim_reload_value--;
		}
//		test_data = htim1.Instance->CNT;
		htim1.Instance->ARR = tim_reload_value;
		htim1.Instance->CNT = 1;
	}

}

void HAL_SYSTICK_Callback(void)
{
	if( ++ refresh_counter>200L){
		refresh_counter = 0;
		flash_counter++;
	}
#ifndef LICEVI_LAMPI_VMESTO_AQAFRESH
	if(aqua_fresh_level == 1){
		if(Gv_miliseconds %30000 >29000L ){
			set_aquafresh(1);
		}
		else {
			set_aquafresh(0);
		}
	}
	else if(aqua_fresh_level == 2){
		if(Gv_miliseconds %15000 >14000L ){
			set_aquafresh(1);
		}
		else {
			set_aquafresh(0);
		}
	}
	else {
		set_aquafresh(0);
	}
#else
	if(aqua_fresh_level > 0){
		set_aquafresh(1);
	}
	else {
		set_aquafresh(0);
	}
#endif

	if(fade_in_counter){
		fade_in_counter--;
//		if(!(fade_in_counter%100)){
//			set_volume(fade_in_counter/100);
//		}
		if(!fade_in_counter){
			//GPIOC->BSRR =  GPIO_BSRR_BS_3; // Internal sound
			silence_counter = 100;
		}
	}

	if(fade_out_counter){
		fade_out_counter--;
//		if(!(fade_out_counter%100)){
//			set_volume(10 - fade_out_counter/100);
//		}
		if(fade_out_counter<=0){
			//TIM_Cmd(TIM14, DISABLE);
		}
		//GPIOC->BRR =  GPIO_BRR_BR_3; // External sound
	}
	if(silence_counter)
	{
		silence_counter--;
		if(!silence_counter)
		{
			fade_out_counter = 100;
		}
	}

	if(startup_delay)
	{
		startup_delay--;
		if(!startup_delay && curr_status == STATUS_WORKING)
		{
			set_colarium_lamps(ON);
			set_fan1(percent_fan1);
			set_fan2(ON);
		}
	}
	if(stop_delay)
	{
		stop_delay--;
		if(!stop_delay && curr_status != STATUS_WORKING)
		{
			set_colarium_lamps(OFF);
		}
	}

	if(Gv_miliseconds++>60000L){
		Gv_miliseconds = 0;
		if (pre_time)
		{
//			play_message(1,message_hurry_up);
			pre_time--;
		}
		else if (main_time) {
			main_time--;
			minute_counter ++;
		}
		else if (cool_time) cool_time--;
		update_status();
	}
	if  (Gv_UART_Timeout){
		Gv_UART_Timeout--;
		if(! Gv_UART_Timeout) {
			rx_state = 0;
			pre_time_sent = 0, main_time_sent = 0, cool_time_sent = 0;
		}
	}

	//	if(zero_crossed) zero_crossed-=10;
	//	if(percent_fan1) set_fan1(zero_crossed && (!(zero_crossed > percent_fan1)));
}

void read_settings(void)
{
	uint8_t result = 0;
	uint16_t  data;

	result += EE_ReadVariable(ADDRESS_ADDRESSE,  &data);
	controller_address = data;
	result += EE_ReadVariable(ADDRESS_PRE_TIME,  &data);
	preset_pre_time = data;
	result += EE_ReadVariable(ADDRESS_COOL_TIME,  &data);
	preset_cool_time = data;
	result += EE_ReadVariable(ADDRESS_EXT_MODE,  &data);
	ext_mode = data;
	result += EE_ReadVariable(ADDRESS_TEMP_MIN,  &data);
	temp_min_threshold = data;
	result += EE_ReadVariable(ADDRESS_TEMP_MAX,  &data);
	temp_max_threshold = data;

	if(result)
	{
		// Set defaults
		preset_pre_time = 7;
		preset_cool_time = 3;
		controller_address = 14;
		temp_min_threshold = 17;
		temp_max_threshold = 85;
		ext_mode = 0;
		work_hours[0] = 0;
		work_hours[1] = 0;
		work_hours[2] = 0;
		write_settings();
		write_stored_time();
	}
}
void read_stored_time(void)
{
	uint16_t  data;
	if(!EE_ReadVariable(ADDRESS_HOURS_H,  &data))
	{
		work_hours[0] = data;
	}
	else
	{
		work_hours[0] = 0;
	}
	if(!EE_ReadVariable(ADDRESS_HOURS_L,  &data))
	{
		work_hours[1] = data;
	}
	else
	{
		work_hours[1] = 0;
	}
	if(!EE_ReadVariable(ADDRESS_MINUTES,  &data))
	{
		work_hours[2] = data;
	}
	else
	{
		work_hours[2] = 0;
	}
}

void write_settings(void)
{
	uint16_t counter;
	for(counter = 0; counter < 3; counter++)
	{
		if(FLASH_COMPLETE != EE_WriteVariable(ADDRESS_ADDRESSE,  controller_address))
		{
			// Second chance
			continue;
		}
		if(FLASH_COMPLETE != EE_WriteVariable(ADDRESS_PRE_TIME,  preset_pre_time))
		{
			// Second chance
			continue;
		}
		if(FLASH_COMPLETE != EE_WriteVariable(ADDRESS_COOL_TIME,  preset_cool_time))
		{
			// Second chance
			continue;
		}
		if(FLASH_COMPLETE != EE_WriteVariable(ADDRESS_EXT_MODE,  ext_mode))
		{
			// Second chance
			continue;
		}
		if(FLASH_COMPLETE != EE_WriteVariable(ADDRESS_TEMP_MIN,  temp_min_threshold))
		{
			// Second chance
			continue;
		}
		if(FLASH_COMPLETE != EE_WriteVariable(ADDRESS_TEMP_MAX,  temp_max_threshold))
		{
			// Second chance
			continue;
		}
		break;
	}
}

void write_stored_time(void)
{
	uint16_t counter;
	for(counter = 0; counter < 3; counter++)
	{
		if(FLASH_COMPLETE != EE_WriteVariable(ADDRESS_HOURS_H,  work_hours[0]))
		{
			// Second chance
			continue;
		}
		if(FLASH_COMPLETE != EE_WriteVariable(ADDRESS_HOURS_L,  work_hours[1]))
		{
			// Second chance
			continue;
		}
		if(FLASH_COMPLETE != EE_WriteVariable(ADDRESS_MINUTES,  work_hours[2]))
		{
			// Second chance
			continue;
		}
		break;
	}
}

void HAL_ADC_ConvCpltCallback(ADC_HandleTypeDef* AdcHandle)
  {
	//CorrectedValue = (((RawValue � RawLow) * ReferenceRange) / RawRange) + ReferenceLow
      g_ADCValue = HAL_ADC_GetValue(AdcHandle);
      g_ADCMeanValue = (g_ADCMeanValue*9 + g_ADCValue)/10;
      raw_temp = 1024 - g_ADCValue;
      g_MeasurementNumber++;
      g_Temperature = analog2tempBed(g_ADCValue); // Must be an error...
      if(g_Temperature > 200)
      {
    	  g_Temperature = 0;
      }
//      g_Temperature = (g_Temperature*9 + (((g_ADCValue - ADC_0_DEGREE_VALUE)*366)/(ADC_36_6_DEGREE_VALUE - ADC_0_DEGREE_VALUE)) + 0)/10;
  }

#define OVERSAMPLENR 4.00 //3.53

// 100k bed thermistor
const float temptable_1[][2]  = {
  {   23 * OVERSAMPLENR, 300 },
  {   25 * OVERSAMPLENR, 295 },
  {   27 * OVERSAMPLENR, 290 },
  {   28 * OVERSAMPLENR, 285 },
  {   31 * OVERSAMPLENR, 280 },
  {   33 * OVERSAMPLENR, 275 },
  {   35 * OVERSAMPLENR, 270 },
  {   38 * OVERSAMPLENR, 265 },
  {   41 * OVERSAMPLENR, 260 },
  {   44 * OVERSAMPLENR, 255 },
  {   48 * OVERSAMPLENR, 250 },
  {   52 * OVERSAMPLENR, 245 },
  {   56 * OVERSAMPLENR, 240 },
  {   61 * OVERSAMPLENR, 235 },
  {   66 * OVERSAMPLENR, 230 },
  {   71 * OVERSAMPLENR, 225 },
  {   78 * OVERSAMPLENR, 220 },
  {   84 * OVERSAMPLENR, 215 },
  {   92 * OVERSAMPLENR, 210 },
  {  100 * OVERSAMPLENR, 205 },
  {  109 * OVERSAMPLENR, 200 },
  {  120 * OVERSAMPLENR, 195 },
  {  131 * OVERSAMPLENR, 190 },
  {  143 * OVERSAMPLENR, 185 },
  {  156 * OVERSAMPLENR, 180 },
  {  171 * OVERSAMPLENR, 175 },
  {  187 * OVERSAMPLENR, 170 },
  {  205 * OVERSAMPLENR, 165 },
  {  224 * OVERSAMPLENR, 160 },
  {  245 * OVERSAMPLENR, 155 },
  {  268 * OVERSAMPLENR, 150 },
  {  293 * OVERSAMPLENR, 145 },
  {  320 * OVERSAMPLENR, 140 },
  {  348 * OVERSAMPLENR, 135 },
  {  379 * OVERSAMPLENR, 130 },
  {  411 * OVERSAMPLENR, 125 },
  {  445 * OVERSAMPLENR, 120 },
  {  480 * OVERSAMPLENR, 115 },
  {  516 * OVERSAMPLENR, 110 },
  {  553 * OVERSAMPLENR, 105 },
  {  591 * OVERSAMPLENR, 100 },
  {  628 * OVERSAMPLENR,  95 },
  {  665 * OVERSAMPLENR,  90 },
  {  702 * OVERSAMPLENR,  85 },
  {  737 * OVERSAMPLENR,  80 },
  {  770 * OVERSAMPLENR,  75 },
  {  801 * OVERSAMPLENR,  70 },
  {  830 * OVERSAMPLENR,  65 },
  {  857 * OVERSAMPLENR,  60 },
  {  881 * OVERSAMPLENR,  55 },
  {  903 * OVERSAMPLENR,  50 },
  {  922 * OVERSAMPLENR,  45 },
  {  939 * OVERSAMPLENR,  40 },
  {  954 * OVERSAMPLENR,  35 },
  {  966 * OVERSAMPLENR,  30 },
  {  977 * OVERSAMPLENR,  25 },
  {  985 * OVERSAMPLENR,  20 },
  {  993 * OVERSAMPLENR,  15 },
  {  999 * OVERSAMPLENR,  10 },
  { 1004 * OVERSAMPLENR,   5 },
  { 1008 * OVERSAMPLENR,   0 },
  { 1012 * OVERSAMPLENR,  -5 },
  { 1016 * OVERSAMPLENR, -10 },
  { 1020 * OVERSAMPLENR, -15 }
};

// 10k thermistor
const float temptable_4[][2] = {
  {    1 * OVERSAMPLENR, 430 },
  {   54 * OVERSAMPLENR, 137 },
  {  107 * OVERSAMPLENR, 107 },
  {  160 * OVERSAMPLENR,  91 },
  {  213 * OVERSAMPLENR,  80 },
  {  266 * OVERSAMPLENR,  71 },
  {  319 * OVERSAMPLENR,  64 },
  {  372 * OVERSAMPLENR,  57 },
  {  425 * OVERSAMPLENR,  51 },
  {  478 * OVERSAMPLENR,  46 },
  {  531 * OVERSAMPLENR,  41 },
  {  584 * OVERSAMPLENR,  35 },
  {  637 * OVERSAMPLENR,  30 },
  {  690 * OVERSAMPLENR,  25 },
  {  743 * OVERSAMPLENR,  20 },
  {  796 * OVERSAMPLENR,  14 },
  {  849 * OVERSAMPLENR,   7 },
  {  902 * OVERSAMPLENR,   0 },
  {  955 * OVERSAMPLENR, -11 },
  { 1008 * OVERSAMPLENR, -35 }
};

// 10k thermistor Chineese
const float temptable_10[][2] = {
  {  1 , 430 },
  { 0x3B8,  100 },
  {  0x978, 36 },
  {  0xCC0,  20 },
  {  0xD81,  13 },
  {  0xE50,  0 },
};
#define COUNT(a) (sizeof(a)/sizeof(*a))
#define BEDTEMPTABLE temptable_10
#define BEDTEMPTABLE_LEN COUNT(BEDTEMPTABLE)
float analog2tempBed(int raw) {

    float celsius = 0;
    unsigned char i;

    for (i = 1; i < BEDTEMPTABLE_LEN; i++) {
      if ((BEDTEMPTABLE[i][0]) > raw) {
        celsius  = BEDTEMPTABLE[i - 1][1] +
                   (raw - BEDTEMPTABLE[i - 1][0]) *
                   (float)(BEDTEMPTABLE[i][1] - BEDTEMPTABLE[i - 1][1]) /
                   (float)(BEDTEMPTABLE[i][0] - BEDTEMPTABLE[i - 1][0]);
        break;
      }
    }

    // Overflow: Set to last value in the table
    if (i == BEDTEMPTABLE_LEN) celsius = BEDTEMPTABLE[i - 1][1];

    return celsius;

}

/* USER CODE END 4 */

void Error_Handler(void)
{
  while(1)
  {
  }
}
